AUTOSAR XML (schema 4-3-0)
package /CAN7/ISignalGroup
  5 x i signal group:
    CAN7_SG_FD7_C100_0: i-signal=CAN7_VCUKeyStatus, system-signal-group=CAN7_SG_FD7_C100_0
    CAN7_SG_FD7_C10_0: i-signal=CAN7_EMotorSpd, system-signal-group=CAN7_SG_FD7_C10_0
    CAN7_SG_FD7_C200_0: i-signal=CAN7_SysPowerMode, system-signal-group=CAN7_SG_FD7_C200_0
    CAN7_SG_FD7_C50_0: i-signal=CAN7_AccPedalPos1, system-signal-group=CAN7_SG_FD7_C50_0
    CAN7_SG_FD7_CE100_0: i-signal=[CAN7_FDC_BCM_DVRSignalL_Cmd, CAN7_FDC_BCM_DVRSignalR_Cmd, CAN7_FDC_BCM_FDoor_Sta, CAN7_FDC_BCM_HBeam_Cmd, CAN7_FDC_BCM_LBeam_Cmd, CAN7_FDC_BCM_MDoor_Sta, CAN7_FDC_BCM_PLamp_Cmd], system-signal-group=CAN7_SG_FD7_CE100_0
package /CAN7/Cluster
  can cluster CAN7: baudrate=500
    can physical channel CAN7: comm-connectors=ConnCAN7
      frame CAN7_DiagFuncReqFT: id 0x7D0, frame-length=8, can-addressing-mode=STANDARD, can-fd-frame-support=false, can-frame-rx-behavior=CAN-20, can-frame-tx-behavior=CAN-20
        n pdu CAN7_DiagFuncReqFT: length=8
      frame CAN7_DiagPhyReqToDATAC: id 0x18DA89F9, frame-length=8, can-addressing-mode=EXTENDED, can-fd-frame-support=false, can-frame-rx-behavior=CAN-20, can-frame-tx-behavior=CAN-20
        n pdu CAN7_DiagPhyReqToDATAC: length=8
      frame CAN7_DiagPhyReqToEDR: id 0x18DA88F9, frame-length=8, can-addressing-mode=EXTENDED, can-fd-frame-support=false, can-frame-rx-behavior=CAN-20, can-frame-tx-behavior=CAN-20
        n pdu CAN7_DiagPhyReqToEDR: length=8
      frame CAN7_DiagPhyReqToNSAS: id 0x18DA90F9, frame-length=8, can-addressing-mode=EXTENDED, can-fd-frame-support=false, can-frame-rx-behavior=CAN-20, can-frame-tx-behavior=CAN-20
        n pdu CAN7_DiagPhyReqToNSAS: length=8
      frame CAN7_DiagRespFromDATAC: id 0x18DAF989, frame-length=8, can-addressing-mode=EXTENDED, can-fd-frame-support=false, can-frame-rx-behavior=CAN-20, can-frame-tx-behavior=CAN-20
        n pdu CAN7_DiagRespFromDATAC: length=8
      frame CAN7_DiagRespFromEDR: id 0x18DAF988, frame-length=8, can-addressing-mode=EXTENDED, can-fd-frame-support=false, can-frame-rx-behavior=CAN-20, can-frame-tx-behavior=CAN-20
        n pdu CAN7_DiagRespFromEDR: length=8
      frame CAN7_DiagRespFromNSAS: id 0x18DAF990, frame-length=8, can-addressing-mode=EXTENDED, can-fd-frame-support=false, can-frame-rx-behavior=CAN-20, can-frame-tx-behavior=CAN-20
        n pdu CAN7_DiagRespFromNSAS: length=8
      frame CAN7_FD7_C100_0: id 0x19F005D0, frame-length=8, can-addressing-mode=EXTENDED, can-fd-frame-support=false, can-frame-rx-behavior=CAN-20, can-frame-tx-behavior=CAN-20
        pdu CAN7_FD7_C100_0: length=8, minimum-delay=0.0, transmission-mode-true-timing=cyclic-timing=time-period=0.1, unused-bit-pattern=0
          mapping CAN7_SG_FD7_C100_0: i-signal-group=CAN7_SG_FD7_C100_0, start-position=0, transfer-property=PENDING
          signal CAN7_VCUKeyStatus: start 0, 2 bit, little-endian, i-signal-type=PRIMITIVE, init-value=constant-reference=Init_CAN7_VCUKeyStatus, base-type=uint8, implementation-data-type=uint8, transfer-property=PENDING
      frame CAN7_FD7_C10_0: id 0xC61D0D1, frame-length=8, can-addressing-mode=EXTENDED, can-fd-frame-support=false, can-frame-rx-behavior=CAN-20, can-frame-tx-behavior=CAN-20
        pdu CAN7_FD7_C10_0: length=8, minimum-delay=0.0, transmission-mode-true-timing=cyclic-timing=time-period=0.01, unused-bit-pattern=0
          mapping CAN7_SG_FD7_C10_0: i-signal-group=CAN7_SG_FD7_C10_0, start-position=0, transfer-property=PENDING
          signal CAN7_EMotorSpd: start 8, 16 bit, little-endian, i-signal-type=PRIMITIVE, init-value=constant-reference=Init_CAN7_EMotorSpd, base-type=uint16, implementation-data-type=uint16, transfer-property=PENDING
      frame CAN7_FD7_C200_0: id 0x18F003EF, frame-length=8, can-addressing-mode=EXTENDED, can-fd-frame-support=false, can-frame-rx-behavior=CAN-20, can-frame-tx-behavior=CAN-20
        pdu CAN7_FD7_C200_0: length=8, minimum-delay=0.0, transmission-mode-true-timing=cyclic-timing=time-period=0.2, unused-bit-pattern=0
          mapping CAN7_SG_FD7_C200_0: i-signal-group=CAN7_SG_FD7_C200_0, start-position=0, transfer-property=PENDING
          signal CAN7_SysPowerMode: start 0, 4 bit, little-endian, i-signal-type=PRIMITIVE, init-value=constant-reference=Init_CAN7_SysPowerMode, base-type=uint8, implementation-data-type=uint8, transfer-property=PENDING
      frame CAN7_FD7_C50_0: id 0xCF00300, frame-length=8, can-addressing-mode=EXTENDED, can-fd-frame-support=false, can-frame-rx-behavior=CAN-20, can-frame-tx-behavior=CAN-20
        pdu CAN7_FD7_C50_0: length=8, minimum-delay=0.0, transmission-mode-true-timing=cyclic-timing=time-period=0.05, unused-bit-pattern=0
          mapping CAN7_SG_FD7_C50_0: i-signal-group=CAN7_SG_FD7_C50_0, start-position=0, transfer-property=PENDING
          signal CAN7_AccPedalPos1: start 8, 8 bit, little-endian, i-signal-type=PRIMITIVE, init-value=constant-reference=Init_CAN7_AccPedalPos1, base-type=uint8, implementation-data-type=uint8, transfer-property=PENDING
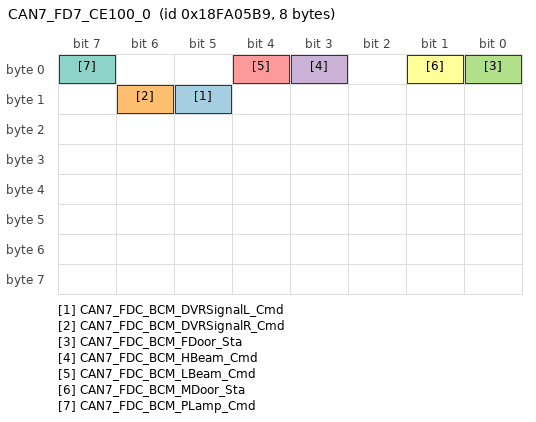
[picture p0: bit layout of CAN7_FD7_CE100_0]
      frame CAN7_FD7_CE100_0: id 0x18FA05B9, frame-length=8, can-addressing-mode=EXTENDED, can-fd-frame-support=false, can-frame-rx-behavior=CAN-20, can-frame-tx-behavior=CAN-20
        pdu CAN7_FD7_CE100_0: length=8, minimum-delay=0.0, transmission-mode-true-timing={cyclic-timing=time-period=0.1, event-controlled-timing={number-of-repetitions=0, repetition-period=0}}, unused-bit-pattern=0
          mapping CAN7_SG_FD7_CE100_0: i-signal-group=CAN7_SG_FD7_CE100_0, start-position=0, transfer-property=TRIGGERED-ON-CHANGE
          signal CAN7_FDC_BCM_DVRSignalL_Cmd: start 13, 1 bit, little-endian, i-signal-type=PRIMITIVE, init-value=constant-reference=Init_CAN7_FDC_BCM_DVRSignalL_Cmd, base-type=uint8, implementation-data-type=uint8, transfer-property=TRIGGERED-ON-CHANGE
          signal CAN7_FDC_BCM_DVRSignalR_Cmd: start 14, 1 bit, little-endian, i-signal-type=PRIMITIVE, init-value=constant-reference=Init_CAN7_FDC_BCM_DVRSignalR_Cmd, base-type=uint8, implementation-data-type=uint8, transfer-property=TRIGGERED-ON-CHANGE
          signal CAN7_FDC_BCM_FDoor_Sta: start 0, 1 bit, little-endian, i-signal-type=PRIMITIVE, init-value=constant-reference=Init_CAN7_FDC_BCM_FDoor_Sta, base-type=uint8, implementation-data-type=uint8, transfer-property=TRIGGERED-ON-CHANGE
          signal CAN7_FDC_BCM_HBeam_Cmd: start 3, 1 bit, little-endian, i-signal-type=PRIMITIVE, init-value=constant-reference=Init_CAN7_FDC_BCM_HBeam_Cmd, base-type=uint8, implementation-data-type=uint8, transfer-property=TRIGGERED-ON-CHANGE
          signal CAN7_FDC_BCM_LBeam_Cmd: start 4, 1 bit, little-endian, i-signal-type=PRIMITIVE, init-value=constant-reference=Init_CAN7_FDC_BCM_LBeam_Cmd, base-type=uint8, implementation-data-type=uint8, transfer-property=TRIGGERED-ON-CHANGE
          signal CAN7_FDC_BCM_MDoor_Sta: start 1, 1 bit, little-endian, i-signal-type=PRIMITIVE, init-value=constant-reference=Init_CAN7_FDC_BCM_MDoor_Sta, base-type=uint8, implementation-data-type=uint8, transfer-property=TRIGGERED-ON-CHANGE
          signal CAN7_FDC_BCM_PLamp_Cmd: start 7, 1 bit, little-endian, i-signal-type=PRIMITIVE, init-value=constant-reference=Init_CAN7_FDC_BCM_PLamp_Cmd, base-type=uint8, implementation-data-type=uint8, transfer-property=TRIGGERED-ON-CHANGE
      frame CAN7_NMm_FUSION_TX: id 0x500, frame-length=8, can-addressing-mode=STANDARD, can-fd-frame-support=false, can-frame-rx-behavior=CAN-20, can-frame-tx-behavior=CAN-20
        nm pdu CAN7_NMm_FUSION_TX: length=8, unused-bit-pattern=0
      frame CAN7_NMm_FUSION_RX: id 0x500, frame-length=8, can-addressing-mode=STANDARD, can-fd-frame-support=false, can-frame-rx-behavior=CAN-20, can-frame-tx-behavior=CAN-20
        nm pdu CAN7_NMm_FUSION_RX: length=8, unused-bit-pattern=0
package /CAN7/ConstantSpecification
  16 x constant specification:
    Init_CAN7_VCUKeyStatus: value-spec=0
    Init_CAN7_EMotorSpd: value-spec=0
    Init_CAN7_SysPowerMode: value-spec=0
    Init_CAN7_AccPedalPos1: value-spec=0
    Init_CAN7_FDC_BCM_DVRSignalL_Cmd: value-spec=0
    Init_CAN7_FDC_BCM_DVRSignalR_Cmd: value-spec=0
    Init_CAN7_FDC_BCM_FDoor_Sta: value-spec=0
    Init_CAN7_FDC_BCM_HBeam_Cmd: value-spec=0
    Init_CAN7_FDC_BCM_LBeam_Cmd: value-spec=0
    Init_CAN7_FDC_BCM_MDoor_Sta: value-spec=0
    Init_CAN7_FDC_BCM_PLamp_Cmd: value-spec=0
    Init_CAN7_SG_FD7_C100_0: value-spec=fields=constant-reference=Init_CAN7_VCUKeyStatus
    Init_CAN7_SG_FD7_C10_0: value-spec=fields=constant-reference=Init_CAN7_EMotorSpd
    Init_CAN7_SG_FD7_C200_0: value-spec=fields=constant-reference=Init_CAN7_SysPowerMode
    Init_CAN7_SG_FD7_C50_0: value-spec=fields=constant-reference=Init_CAN7_AccPedalPos1
    Init_CAN7_SG_FD7_CE100_0: value-spec=fields=[Init_CAN7_FDC_BCM_DVRSignalL_Cmd, Init_CAN7_FDC_BCM_DVRSignalR_Cmd, Init_CAN7_FDC_BCM_FDoor_Sta, Init_CAN7_FDC_BCM_HBeam_Cmd, Init_CAN7_FDC_BCM_LBeam_Cmd, Init_CAN7_FDC_BCM_MDoor_Sta, Init_CAN7_FDC_BCM_PLamp_Cmd]
package /CAN7/ImplementationDataTypes
  5 x impl type, all with category=STRUCTURE:
    DT_CAN7_SG_FD7_C100_0
      element CAN7_VCUKeyStatus: implementation-data-type=uint8
    DT_CAN7_SG_FD7_C10_0
      element CAN7_EMotorSpd: implementation-data-type=uint16
    DT_CAN7_SG_FD7_C200_0
      element CAN7_SysPowerMode: implementation-data-type=uint8
    DT_CAN7_SG_FD7_C50_0
      element CAN7_AccPedalPos1: implementation-data-type=uint8
    DT_CAN7_SG_FD7_CE100_0
      7 x element, all with category=TYPE_REFERENCE, implementation-data-type=uint8:
        CAN7_FDC_BCM_DVRSignalL_Cmd
        CAN7_FDC_BCM_DVRSignalR_Cmd
        CAN7_FDC_BCM_FDoor_Sta
        CAN7_FDC_BCM_HBeam_Cmd
        CAN7_FDC_BCM_LBeam_Cmd
        CAN7_FDC_BCM_MDoor_Sta
        CAN7_FDC_BCM_PLamp_Cmd
